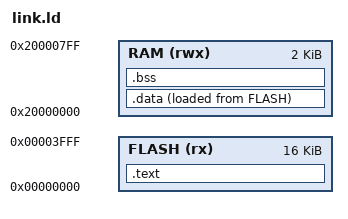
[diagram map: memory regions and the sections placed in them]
OUTPUT_ARCH(riscv)
ENTRY(_start)

MEMORY
{
    FLASH (rx)  : ORIGIN = 0x00000000, LENGTH = 16K
    RAM   (rwx) : ORIGIN = 0x20000000, LENGTH = 2K
}

SECTIONS
{
    .text :
    {
        KEEP(*(.init))
        *(.text .text.*)
        *(.rodata .rodata.*)
        . = ALIGN(4);
    } > FLASH

    .data :
    {
        . = ALIGN(4);
        _data_start = .;
        __global_pointer$ = . + 0x800;
        *(.sdata .sdata.* .data .data.*)
        *(.ramtext .ramtext.*)
        . = ALIGN(4);
        _data_end = .;
    } > RAM AT > FLASH
    _data_load = LOADADDR(.data);

    .bss (NOLOAD) :
    {
        . = ALIGN(4);
        _bss_start = .;
        *(.sbss .sbss.* .bss .bss.* COMMON)
        . = ALIGN(4);
        _bss_end = .;
    } > RAM

    _stack_top = ORIGIN(RAM) + LENGTH(RAM);
    ASSERT(_bss_end <= _stack_top - 256, "Not enough stack space")
}
